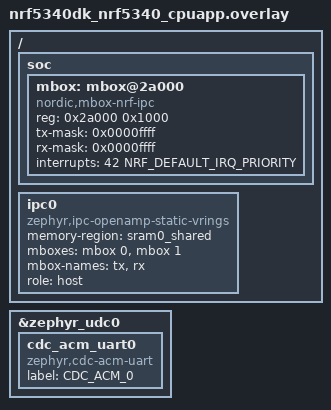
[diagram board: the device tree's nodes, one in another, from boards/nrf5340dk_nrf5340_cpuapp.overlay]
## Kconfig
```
#
# Copyright (c) 2022 Nordic Semiconductor
#
# SPDX-License-Identifier: LicenseRef-Nordic-5-Clause
#

source "Kconfig.zephyr"

menu "Nordic Remote Shell sample"

config REMOTE_SHELL_TX_RING_BUFFER_SIZE
	int "Set TX ring buffer size"
	default 64
	help
	  If UART is utilizing DMA transfers then increasing ring buffer size
	  increases transfers length and reduces number of interrupts. It is used
          to collect data from transport medium and passing it to remote shell.

config REMOTE_SHELL_RX_RING_BUFFER_SIZE
	int "Set RX ring buffer size"
	default 64
	help
	  RX ring buffer size, used to collect data received from remote shell and passing
          them to choosen transport medium.

config REMOTE_SHELL_UART_DEV
	string "UART device name"
	default "CDC_ACM_0"
	help
	  Name of the used UART device. The sample uses cdc_acm_0 by default.
	  The UART device should not be used as logger backend.

endmenu
```

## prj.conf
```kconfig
#
# Copyright (c) 2022 Nordic Semiconductor ASA
#
# SPDX-License-Identifier: LicenseRef-Nordic-5-Clause
#
################################################################################

CONFIG_STDOUT_CONSOLE=y

CONFIG_USB_DEVICE_STACK=y
CONFIG_USB_DEVICE_PRODUCT="Nordic Radio Test USB sample"
CONFIG_USB_DEVICE_VID=0x1915
CONFIG_USB_DEVICE_PID=0x530E

CONFIG_LOG=y

CONFIG_USB_DRIVER_LOG_LEVEL_ERR=y
CONFIG_USB_DEVICE_LOG_LEVEL_ERR=y

CONFIG_SERIAL=y
CONFIG_UART_INTERRUPT_DRIVEN=y
CONFIG_UART_LINE_CTRL=y

CONFIG_IPC_SERVICE=y
CONFIG_IPC_SERVICE_BACKEND_RPMSG=y
CONFIG_MBOX=y

CONFIG_MBOX_NRFX_IPC=y

CONFIG_HEAP_MEM_POOL_SIZE=4096

CONFIG_BOARD_ENABLE_CPUNET=y
```

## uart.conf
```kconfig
#
# Copyright (c) 2022 Nordic Semiconductor ASA
#
# SPDX-License-Identifier: LicenseRef-Nordic-5-Clause
#
################################################################################

CONFIG_STDOUT_CONSOLE=y

CONFIG_REMOTE_SHELL_UART_DEV="UART_0"

CONFIG_SERIAL=y
CONFIG_UART_INTERRUPT_DRIVEN=y
CONFIG_RING_BUFFER=y

CONFIG_IPC_SERVICE=y
CONFIG_IPC_SERVICE_BACKEND_RPMSG=y
CONFIG_MBOX=y

CONFIG_MBOX_NRFX_IPC=y
CONFIG_NRFX_UARTE0=y

CONFIG_HEAP_MEM_POOL_SIZE=4096

# Config logger
CONFIG_LOG=y
CONFIG_USE_SEGGER_RTT=y
CONFIG_LOG_BACKEND_RTT=y
CONFIG_LOG_BACKEND_UART=n

CONFIG_REMOTE_SHELL_TX_RING_BUFFER_SIZE=1024

CONFIG_BOARD_ENABLE_CPUNET=y
```

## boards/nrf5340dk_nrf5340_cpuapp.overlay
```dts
/*
 * Copyright (c) 2021 Nordic Semiconductor ASA
 *
 * SPDX-License-Identifier: LicenseRef-Nordic-5-Clause
 */
 
&zephyr_udc0 {
	cdc_acm_uart0 {
		compatible = "zephyr,cdc-acm-uart";
		label = "CDC_ACM_0";
	};
};

/ {
	soc {
		/delete-node/ ipc@41012000;

		mbox: mbox@2a000 {
			compatible = "nordic,mbox-nrf-ipc";
			reg = <0x2a000 0x1000>;
			tx-mask = <0x0000ffff>;
			rx-mask = <0x0000ffff>;
			interrupts = <42 NRF_DEFAULT_IRQ_PRIORITY>;
			#mbox-cells = <1>;
			status = "okay";
		};
	};

	ipc0: ipc0 {
		compatible = "zephyr,ipc-openamp-static-vrings";
		memory-region = <&sram0_shared>;
		mboxes = <&mbox 0>, <&mbox 1>;
		mbox-names = "tx", "rx";
		role = "host";
		status = "okay";
	};
};
```

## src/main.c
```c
/*
 * Copyright (c) 2022 Nordic Semiconductor ASA
 *
 * SPDX-License-Identifier: LicenseRef-Nordic-5-Clause
 */

#include <stdio.h>
#include <string.h>
#include <device.h>
#include <drivers/uart.h>
#include <zephyr.h>
#include <sys/ring_buffer.h>
#include <sys/atomic.h>
#include <usb/usb_device.h>

#include "shell_ipc_host.h"

#include <logging/log.h>

#define HOST_WAIT_TIME 1000000

LOG_MODULE_REGISTER(remote_shell);

RING_BUF_DECLARE(rx_ringbuf, CONFIG_REMOTE_SHELL_RX_RING_BUFFER_SIZE);
RING_BUF_DECLARE(tx_ringbuf, CONFIG_REMOTE_SHELL_TX_RING_BUFFER_SIZE);

K_SEM_DEFINE(shell_ipc_write_sem, 0, 1);

static const struct uart_irq_context {
	struct ring_buf *rx_buf;
	struct ring_buf *tx_buf;
	struct k_sem *write_sem;
} uart_context = {
	.rx_buf = &rx_ringbuf,
	.tx_buf = &tx_ringbuf,
	.write_sem = &shell_ipc_write_sem
};

static void uart_dtr_wait(const struct device *dev)
{
	if (IS_ENABLED(CONFIG_UART_LINE_CTRL)) {
		int dtr, err;

		while (true) {
			err = uart_line_ctrl_get(dev, UART_LINE_CTRL_DTR, &dtr);
			if (err == -ENOSYS || err == -ENOTSUP) {
				break;
			}
			if (dtr) {
				break;
			}
			/* Give CPU resources to low priority threads. */
			k_sleep(K_MSEC(100));
		}
	}
}

static void ipc_host_receive(const uint8_t *data, size_t len, void *context)
{
	int recv_len;
	const struct device *uart_dev = context;

	if (!data || (len == 0)) {
		return;
	}

	recv_len = ring_buf_put(&tx_ringbuf, data, len);
	if (recv_len < len) {
		LOG_INF("TX ring buffer full. Dropping %d bytes", len - recv_len);
	}

	uart_irq_tx_enable(uart_dev);
}

static void uart_irq_handler(const struct device *dev, void *user_data)
{
	int err;
	const struct uart_irq_context *uart_ctrl = user_data;

	uart_irq_update(dev);

	if (uart_irq_rx_ready(dev)) {
		int recv_len = 0;
		uint8_t *data;

		recv_len = ring_buf_put_claim(uart_ctrl->rx_buf, &data, uart_ctrl->rx_buf->size);
		if (recv_len) {
			recv_len = uart_fifo_read(dev, data, recv_len);
			if (recv_len < 0) {
				LOG_ERR("Failed to read UART FIFO, err %d", recv_len);
				recv_len = 0;
			} else {
				ring_buf_put_finish(uart_ctrl->rx_buf, recv_len);
			}

			if (recv_len) {
				k_sem_give(uart_ctrl->write_sem);
			}
		}
	}

	if (uart_irq_tx_ready(dev)) {
		int send_len = 0;
		uint8_t *data;

		send_len  = ring_buf_get_claim(uart_ctrl->tx_buf, &data, uart_ctrl->tx_buf->size);
		if (send_len) {
			if (IS_ENABLED(CONFIG_UART_LINE_CTRL)) {
				uart_dtr_wait(dev);
			}

			send_len = uart_fifo_fill(dev, data, send_len);
			err = ring_buf_get_finish(uart_ctrl->tx_buf, send_len);
			__ASSERT_NO_MSG(err == 0);
		} else {
			uart_irq_tx_disable(dev);
		}
	}
}

void main(void)
{
        int err;
	const struct device *dev;
	uint32_t baudrate = 0;

	dev = device_get_binding(CONFIG_REMOTE_SHELL_UART_DEV);
	if (!device_is_ready(dev)) {
		LOG_ERR("Device not ready");
		return;
	}

	if (IS_ENABLED(CONFIG_USB_DEVICE_STACK)) {
		err = usb_enable(NULL);
		if (err != 0) {
			LOG_ERR("Failed to enable USB, err %d", err);
			return;
		}
	}

	if (IS_ENABLED(CONFIG_UART_LINE_CTRL)) {
		LOG_INF("Wait for DTR");

		uart_dtr_wait(dev);

		LOG_INF("DTR set");

		/* They are optional, we use them to test the interrupt endpoint */
		err = uart_line_ctrl_set(dev, UART_LINE_CTRL_DCD, 1);
		if (err) {
			LOG_WRN("Failed to set DCD, err %d", err);
		}

		err = uart_line_ctrl_set(dev, UART_LINE_CTRL_DSR, 1);
		if (err) {
			LOG_WRN("Failed to set DSR, err %d", err);
		}

		/* Wait 1 sec for the host to do all settings */
		k_busy_wait(HOST_WAIT_TIME);

		err = uart_line_ctrl_get(dev, UART_LINE_CTRL_BAUD_RATE, &baudrate);
		if (err) {
			LOG_WRN("Failed to get baudrate, err %d", err);
		} else {
			LOG_INF("Baudrate detected: %d", baudrate);
		}
	}

	uart_irq_callback_user_data_set(dev, uart_irq_handler, (void *)&uart_context);

	/* Enable rx interrupts */
	uart_irq_rx_enable(dev);

	err = shell_ipc_host_init(ipc_host_receive, (void *)dev);
	if (err) {
		LOG_ERR("Shell IPC host initialization failed, err %d", err);
		return;
	}

	for (;;) {
		uint8_t *data;
		uint32_t data_size;

		k_sem_take(&shell_ipc_write_sem, K_FOREVER);

		data_size = ring_buf_get_claim(&rx_ringbuf, &data, rx_ringbuf.size);

		if (data_size) {
			data_size = shell_ipc_host_write(data, data_size);
			if (data_size >= 0) {
				LOG_DBG("Sent %d bytes", data_size);
				ring_buf_get_finish(&rx_ringbuf, data_size);
			} else {
				LOG_INF("Failed to send %d bytes (%d error)",
					data_size, data_size);
			}
		}
	}
}
```

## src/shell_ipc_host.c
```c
/*
 * Copyright (c) 2022 Nordic Semiconductor ASA
 *
 * SPDX-License-Identifier: LicenseRef-Nordic-5-Clause
 */

#include <kernel.h>
#include <ipc/ipc_service.h>
#include <device.h>

#include "shell_ipc_host.h"

struct shell_ipc_host {
        struct ipc_ept ept;
        struct ipc_ept_cfg ept_cfg;
        struct k_sem ipc_bond_sem;
        shell_ipc_host_recv_cb cb;
        void *context;
};

static struct shell_ipc_host ipc_host;

static void bound(void *priv)
{
        struct shell_ipc_host *ipc = priv;

        k_sem_give(&ipc->ipc_bond_sem);
}

static void received(const void *data, size_t len, void *priv)
{
        struct shell_ipc_host *ipc = priv;

        if (!data || (len == 0)) {
                return;
        }

        if (ipc->cb) {
                ipc->cb(data, len, ipc->context);
        }
}

static int ipc_init(void)
{
        int err;
        const struct device *dev = DEVICE_DT_GET(DT_NODELABEL(ipc0));

        if (!device_is_ready(dev)) {
                return -ENODEV;
        }

        err = ipc_service_open_instance(dev);
        if (err) {
                return err;
        }

        err = k_sem_init(&ipc_host.ipc_bond_sem, 0, 1);
        if (err) {
                return err;
        }

        ipc_host.ept_cfg.name = "remote shell";
        ipc_host.ept_cfg.cb.bound = bound;
        ipc_host.ept_cfg.cb.received = received;
        ipc_host.ept_cfg.priv = &ipc_host;

        err = ipc_service_register_endpoint(dev, &ipc_host.ept, &ipc_host.ept_cfg);
        if (err) {
                return err;
        }

        k_sem_take(&ipc_host.ipc_bond_sem, K_FOREVER);

        return 0;
}

int shell_ipc_host_init(shell_ipc_host_recv_cb cb, void *context)
{
        if (!cb) {
                return -EINVAL;
        }

        ipc_host.cb = cb;
        ipc_host.context = context;

        return ipc_init();
}

int shell_ipc_host_write(const uint8_t *data, size_t len)
{
        if (!data || (len == 0)) {
                return -EINVAL;
        }

        __ASSERT_NO_MSG(ipc_host.ept.instance);

        return ipc_service_send(&ipc_host.ept, data, len);
}
```

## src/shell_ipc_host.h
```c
/*
 * Copyright (c) 2022 Nordic Semiconductor ASA
 *
 * SPDX-License-Identifier: LicenseRef-Nordic-5-Clause
 */

#ifndef SHELL_IPC_HOST_H_
#define SHELL_IPC_HOST_H_

#include <stdint.h>
#include <stddef.h>

#ifdef __cplusplus
        extern "C" {
#endif

typedef void (*shell_ipc_host_recv_cb)(const uint8_t *data, size_t len, void *context);

int shell_ipc_host_init(shell_ipc_host_recv_cb cb, void *context);

int shell_ipc_host_write(const uint8_t *data, size_t len);

#ifdef __cplusplus
}
#endif

#endif /* SHELL_IPC_HOST_H_ */
```
